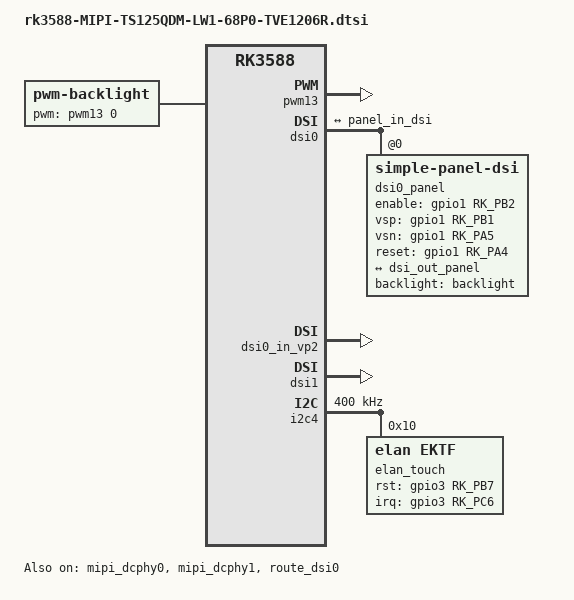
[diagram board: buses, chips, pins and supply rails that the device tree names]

#include <dt-bindings/gpio/gpio.h>
#include <dt-bindings/pwm/pwm.h>
#include <dt-bindings/pinctrl/rockchip.h>
#include <dt-bindings/input/rk-input.h>
#include <dt-bindings/display/drm_mipi_dsi.h>
#include <dt-bindings/display/rockchip_vop.h>

/ {
	backlight: backlight {
        status = "okay";
		compatible = "pwm-backlight";
		pwms = <&pwm13 0 25000 0>;
		brightness-levels = <
			  0   1   2   3   4   5   6   7
			  8   9  10  11  12  13  14  15
			 16  17  18  19  20  21  22  23
			 24  25  26  27  28  29  30  31
			 32  33  34  35  36  37  38  39
			 40  41  42  43  44  45  46  47
			 48  49  50  51  52  53  54  55
			 56  57  58  59  60  61  62  63
			 64  65  66  67  68  69  70  71
			 72  73  74  75  76  77  78  79
			 80  81  82  83  84  85  86  87
			 88  89  90  91  92  93  94  95
			 96  97  98  99 100 101 102 103
			104 105 106 107 108 109 110 111
			112 113 114 115 116 117 118 119
			120 121 122 123 124 125 126 127
			128 129 130 131 132 133 134 135
			136 137 138 139 140 141 142 143
			144 145 146 147 148 149 150 151
			152 153 154 155 156 157 158 159
			160 161 162 163 164 165 166 167
			168 169 170 171 172 173 174 175
			176 177 178 179 180 181 182 183
			184 185 186 187 188 189 190 191
			192 193 194 195 196 197 198 199
			200 201 202 203 204 205 206 207
			208 209 210 211 212 213 214 215
			216 217 218 219 220 221 222 223
			224 225 226 227 228 229 230 231
			232 233 234 235 236 237 238 239
			240 241 242 243 244 245 246 247
			248 249 250 251 252 253 254 255
		>;
		default-brightness-level = <128>;
	};

};

&pwm13 {
	status = "okay";
	pinctrl-names = "active";
	pinctrl-0 = <&pwm13m1_pins>;
};

/* mipi_dcphy0 should be enabled if dsi0 enabled */
&mipi_dcphy0 {
	status = "okay";
};

&mipi_dcphy1 {
	status = "okay";
};

&dsi0 {
	status = "okay";
	rockchip,dual-channel = <&dsi1>;
	//rockchip,lane-rate = <900>;

	dsi0_panel: panel@0 {
		status = "okay";
		compatible = "simple-panel-dsi";
		reg = <0>;
		backlight = <&backlight>;

		enable-gpios = <&gpio1 RK_PB2 GPIO_ACTIVE_HIGH>;
		vsp-gpios = <&gpio1 RK_PB1 GPIO_ACTIVE_HIGH>;
		vsn-gpios = <&gpio1 RK_PA5 GPIO_ACTIVE_HIGH>;
		reset-gpios = <&gpio1 RK_PA4 GPIO_ACTIVE_HIGH>;
		pinctrl-names = "default";
		pinctrl-0 = <&vcc1v8_lcd_en &vsp5v8_lcd_en &vsn5v8_lcd_en &lcd_rst_gpio>;

		enable-delay-ms = <10>;
		vsp-delay-ms = <5>;
		vsn-delay-ms = <5>;
		reset-delay-ms = <10>;
		prepare-delay-ms = <5>;
		unprepare-delay-ms = <75>;
		disable-delay-ms = <5>;
		init-delay-ms = <15>;

		dsi,flags = <(MIPI_DSI_MODE_VIDEO | MIPI_DSI_MODE_VIDEO_BURST |
		              MIPI_DSI_MODE_LPM | MIPI_DSI_MODE_EOT_PACKET)>;
		dsi,format = <MIPI_DSI_FMT_RGB888>;
		dsi,lanes  = <8>;

		panel-init-sequence = [
			29 00 04 B9 83 10 2E
			29 00 05 D1 67 0C FF 05
			29 00 12 B1 10 FA AF AF 26 26 91 07 1B 36 36 36 36 22 21 15 00
			29 00 03 D2 26 26
			29 00 11 B2 00 40 6A 00 00 22 62 16 10 00 00 00 15 20 D7 00
			13 00 02 BD 03
			13 00 02 B2 80
			13 00 02 BD 00
			29 00 11 B4 63 5D 63 5D 65 5F 65 5F 01 71 01 58 00 FF 00 FF
			13 00 02 E9 CD
			13 00 02 BB 01
			13 00 02 E9 00
			29 00 04 BF FC 85 80
			29 00 09 BA 70 03 A8 83 F2 00 80 0D
			29 00 2C D3 00 00 00 00 01 04 00 14 00 13 27 24 41 1A 1A 04 04 32 10 21 00 21 32 10 1F 00 1F 32 38 B2 08 B2 00 00 14 47 01 55 13 37 01 55 0E
			29 00 2F E0 00 05 0D 14 1B 2E 46 4F 58 56 71 78 80 90 90 9A A3 B6 B5 59 61 6B 73 00 05 0D 14 1B 2E 46 4F 58 56 71 78 80 90 90 9A A3 B6 B5 59 61 6B 73
			13 00 02 BD 01
			29 00 05 B1 01 9B 01 31
			29 00 0C D3 01 40 7C 00 00 11 10 00 0E 00 01
			13 00 02 BD 02
			29 00 07 B4 4E 00 33 11 33 88
			29 00 04 BF F2 00 02
			13 00 02 BD 00
			29 00 0F C0 23 23 22 11 A2 17 00 80 00 00 08 00 63 63
			13 00 02 C6 F9
			13 00 02 C7 30
			29 00 09 C8 00 04 04 00 00 82 13 FF
			29 00 04 D0 07 04 05
			29 00 2D D5 18 18 3B 3B 3B 3B 3B 3B 18 18 18 18 18 18 20 20 21 21 3A 3A 19 19 3B 3B 3B 3B AE AE 18 18 18 18 02 02 03 03 00 00 01 01 3A 3A 3A 3A
			29 00 2D D6 18 18 3B 3B 3B 3B 3B 3B 18 18 18 18 18 18 21 21 20 20 19 19 3A 3A 3B 3B 3B 3B 2E 2E 18 18 18 18 01 01 00 00 03 03 02 02 3A 3A 3A 3A
			29 00 0D D8 2A AA AB FA FF A0 2A AA AB FA FF A0
			29 00 18 E7 12 13 02 02 43 43 0E 0E 1E 1E 2D 5F 24 5D 01 27 00 00 00 00 17 00 68
			13 00 02 BD 01
			29 00 0D D8 2A AB FF FF FF F0 2A AB FF FF FF F0
			29 00 08 E7 02 2C 01 C4 0D B8 0E
			13 00 02 BD 02
			29 00 1D E7 00 01 00 01 00 00 11 00 00 00 00 00 00 00 00 00 00 00 00 00 00 00 00 00 81 00 02 40
			29 00 0D D8 2A AB FF FF FF F0 2A AB FF FF FF F0
			13 00 02 BD 03
			29 00 19 D8 2A AA BE AA AA F0 2A AA BE AA AA F0 2A AB FF FF FF F0 2A AB FF FF FF F0
			13 00 02 BD 00
			13 00 02 CC 02
			29 00 03 BE 11 96
			13 00 02 D9 3F
			29 00 04 B9 77 88 99
			13 00 02 BD 01
			29 00 05 CB 80 36 12 06
			13 00 02 BD 00
			29 00 04 B9 83 10 2E
			29 00 03 E1 01 06
			29 00 04 B9 00 00 00
			05 00 01 11
			05 00 01 29
		];

		panel-exit-sequence = [
			29 00 02 00 00
			29 00 03 99 95 27
			05 01 01 28
			05 01 01 10
		];

		disp_timings0: display-timings {
			native-mode = <&dsi0_timing0>;
			dsi0_timing0: timing0 {
				clock-frequency = <282000000>;
				hactive = <1600>;
				vactive = <2560>;
				hfront-porch = <36>;
				hsync-len = <28>;
				hback-porch = <26>;
				vfront-porch = <98>;
				vsync-len = <8>;
				vback-porch = <28>;
				hsync-active = <0>;
				vsync-active = <0>;
				de-active = <0>;
				pixelclk-active = <0>;
			};
		};

		ports {
			#address-cells = <1>;
			#size-cells = <0>;

			port@0 {
				reg = <0>;
				panel_in_dsi: endpoint {
					remote-endpoint = <&dsi_out_panel>;
				};
			};
		};
	};

	ports {
		#address-cells = <1>;
		#size-cells = <0>;

		port@1 {
			reg = <1>;
			dsi_out_panel: endpoint {
				remote-endpoint = <&panel_in_dsi>;
			};
		};
	};
};

&route_dsi0 {
	status = "okay";
	connect = <&vp2_out_dsi0>;
};

&dsi0_in_vp2 {
	status = "okay";
};

&dsi0_in_vp3 {
	status = "disabled";
};

/* mipi_dcphy0 should be enabled if dsi0 enabled */
&dsi0 {
	status = "okay";
};

&dsi1 {
	status = "okay";
};

&dsi1_in_vp2 {
	status = "disabled";
};

&dsi1_in_vp3 {
	status = "disabled";
};

&i2c4 {
	status = "okay";
	pinctrl-names = "default";
	pinctrl-0 = <&i2c4m3_xfer>;
	clock-frequency = <400000>;

	elan_touch: elan_ktf@10 {
		status = "okay";
		compatible = "elan,ektf";
		reg = <0x10>;
		pinctrl-names = "default";
		pinctrl-0 = <&elan_pins>;
		elan,rst-gpio = <&gpio3 RK_PB7 GPIO_ACTIVE_HIGH>;
		elan,irq-gpio = <&gpio3 RK_PC6 IRQ_TYPE_LEVEL_LOW>;
		chip_type = <0x01>;	/* 1:HID IIC, 0: NORMAL IIC */
		report_type = <0x01>;	/* 1:B protocol, 0:A protocol */
	};
};

&pinctrl {

	touch {
		elan_pins: elan-pins {
			rockchip,pins =
				<3 RK_PB7 RK_FUNC_GPIO &pcfg_pull_up>,
				<3 RK_PC6 RK_FUNC_GPIO &pcfg_pull_none>;
		};
	};

	lcd {
		lcd_rst_gpio: lcd-rst-gpio {
			rockchip,pins = <1 RK_PA4 RK_FUNC_GPIO &pcfg_pull_none>;
		};

		vcc1v8_lcd_en: vcc1v8-lcd-en {
			rockchip,pins = <1 RK_PB2 RK_FUNC_GPIO &pcfg_pull_none>;
		};

		vsp5v8_lcd_en: vsp5v8-lcd-en {
			rockchip,pins = <1 RK_PB1 RK_FUNC_GPIO &pcfg_pull_none>;
		};

		vsn5v8_lcd_en: vsn5v8-lcd-en {
			rockchip,pins = <1 RK_PA5 RK_FUNC_GPIO &pcfg_pull_none>;
		};
	};
};
